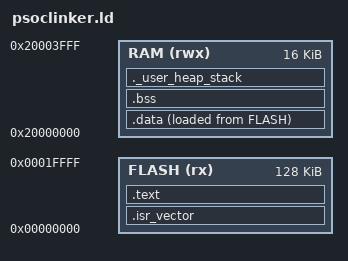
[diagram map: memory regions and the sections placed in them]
/* Linker script for PSoC 4100S Plus */

/* Entry Point */
ENTRY(Reset_Handler)

/* Memory Layout */
/* Update LENGTH based on specific device variant (e.g., 64K, 128K, 256K) */
MEMORY
{
    FLASH (rx) : ORIGIN = 0x00000000, LENGTH = 128K
    RAM   (rwx) : ORIGIN = 0x20000000, LENGTH = 16K
}

/* Sections */
SECTIONS
{
    /* Stack pointer at end of RAM */
    _estack = ORIGIN(RAM) + LENGTH(RAM);

    /* Vector table goes at start of Flash */
    .isr_vector :
    {
        . = ALIGN(4);
        KEEP(*(.isr_vector))
        . = ALIGN(4);
    } > FLASH

    /* Code and read-only data */
    .text :
    {
        . = ALIGN(4);
        *(.text)           /* .text sections (code) */
        *(.text*)          /* .text* sections (code) */
        *(.rodata)         /* .rodata sections (constants, strings, etc.) */
        *(.rodata*)        /* .rodata* sections (constants, strings, etc.) */
        . = ALIGN(4);
        _etext = .;        /* define a global symbol at end of code */
    } > FLASH

    /* Initialized data sections goes into RAM, load LMA copy after code */
    _sidata = LOADADDR(.data);

    .data :
    {
        . = ALIGN(4);
        _sdata = .;        /* create a global symbol at data start */
        *(.data)           /* .data sections */
        *(.data*)          /* .data* sections */
        . = ALIGN(4);
        _edata = .;        /* define a global symbol at data end */
    } > RAM AT> FLASH

    /* Uninitialized data section */
    .bss :
    {
        . = ALIGN(4);
        _sbss = .;         /* define a global symbol at bss start */
        *(.bss)
        *(.bss*)
        *(COMMON)
        . = ALIGN(4);
        _ebss = .;         /* define a global symbol at bss end */
    } > RAM

    /* User_heap_stack section, used to check that there is enough RAM left */
    ._user_heap_stack :
    {
        . = ALIGN(8);
        . = . + 0x400; /* 1KB reserved for stack/heap safety check */
    } > RAM
}
